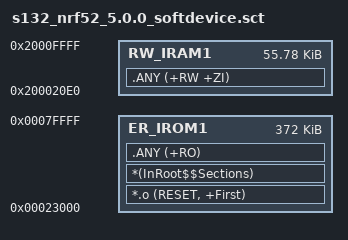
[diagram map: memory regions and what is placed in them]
; *************************************************************
; *** Scatter-Loading Description File generated by uVision ***
; *************************************************************

LR_IROM1 0x00023000 0x0005D000  {    ; load region size_region
  ER_IROM1 0x00023000 0x0005D000  {  ; load address = execution address
   *.o (RESET, +First)
   *(InRoot$$Sections)
   .ANY (+RO)
  }
  RW_IRAM1 0x200020E0 0x0000DF20  {  ; RW data
   .ANY (+RW +ZI)
  }
}

